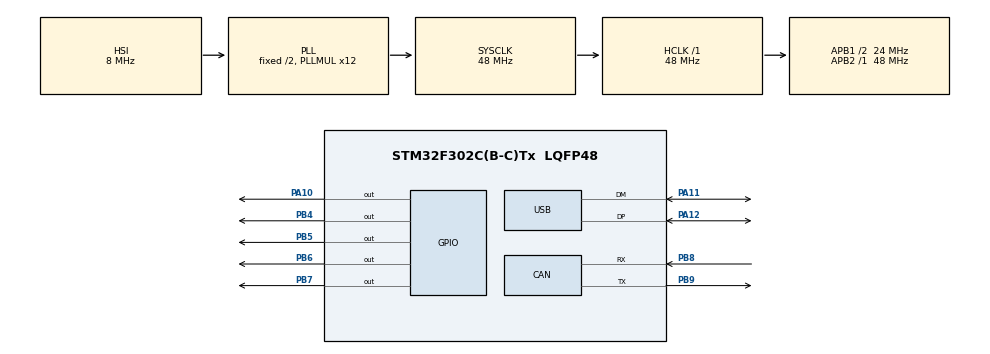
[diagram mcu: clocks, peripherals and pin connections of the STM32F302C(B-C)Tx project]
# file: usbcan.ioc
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CAN.CalculateTimeQuantum=666.6666666666666
Mcu.Family=STM32F3
Mcu.Name=STM32F302C(B-C)Tx
Mcu.Package=LQFP48
NVIC.PriorityGroup=NVIC_PRIORITYGROUP_4
NVIC.USB_LP_IRQn=true\:0\:0\:false\:false\:true\:false\:true
PA10.Signal=GPIO_Output
PA11.Mode=Device
PA11.Signal=USB_DM
PA12.Mode=Device
PA12.Signal=USB_DP
PA13.Mode=Serial_Wire
PA13.Signal=SYS_JTMS-SWDIO
PA14.Mode=Serial_Wire
PA14.Signal=SYS_JTCK-SWCLK
PB4.Signal=GPIO_Output
PB5.Signal=GPIO_Output
PB6.Signal=GPIO_Output
PB7.Signal=GPIO_Output
PB8.Mode=Master
PB8.Signal=CAN_RX
PB9.Mode=Master
PB9.Signal=CAN_TX
ProjectManager.HeapSize=0x200
ProjectManager.StackSize=0x400
ProjectManager.TargetToolchain=STM32CubeIDE
RCC.AHBFreq_Value=48000000
RCC.APB1CLKDivider=RCC_HCLK_DIV2
RCC.APB1Freq_Value=24000000
RCC.APB1TimFreq_Value=48000000
RCC.APB2Freq_Value=48000000
RCC.APB2TimFreq_Value=48000000
RCC.CortexFreq_Value=48000000
RCC.HCLKFreq_Value=48000000
RCC.HSE_VALUE=8000000
RCC.HSI_VALUE=8000000
RCC.LSE_VALUE=32768
RCC.PLLMUL=RCC_PLL_MUL12
RCC.PLLSource=RCC_PLLSOURCE_HSI
RCC.PLLSourceVirtualString=RCC_PLLSOURCE_HSI
RCC.SYSCLKFreq_VALUE=48000000
RCC.SYSCLKSourceVirtual=RCC_SYSCLKSOURCE_PLLCLK
RCC.USBFreq_Value=48000000
USB_DEVICE.CLASS_NAME_FS=CDC
USB_DEVICE.VirtualMode=Cdc
USB_DEVICE.VirtualModeFS=Cdc_FS
VP_USB_DEVICE_VS_USB_DEVICE_CDC_FS.Mode=CDC_FS
board=custom

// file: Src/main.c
/* USER CODE BEGIN Header */
/**
  ******************************************************************************
  * @file           : main.c
  * @brief          : Main program body
  ******************************************************************************
  * @attention
  *
  * <h2><center>&copy; Copyright (c) 2019 STMicroelectronics.
  * All rights reserved.</center></h2>
  *
  * This software component is licensed by ST under Ultimate Liberty license
  * SLA0044, the "License"; You may not use this file except in compliance with
  * the License. You may obtain a copy of the License at:
  *                             www.st.com/SLA0044
  *
  ******************************************************************************
  */
/* USER CODE END Header */

#include "main.h"
#include "usb_device.h"

CAN_HandleTypeDef hcan;

void SystemClock_Config(void);
static void MX_GPIO_Init(void);
static void MX_CAN_Init(void);

/* USER CODE BEGIN 0 */

extern USBD_HandleTypeDef hUsbDeviceFS;
/* USER CODE END 0 */

int main(void)
{

  /* MCU Configuration--------------------------------------------------------*/

  /* Reset of all peripherals, Initializes the Flash interface and the Systick. */
  HAL_Init();

  /* Configure the system clock */
  SystemClock_Config();

  /* Initialize all configured peripherals */
  MX_GPIO_Init();
  MX_CAN_Init();
  MX_USB_DEVICE_Init();
  /* USER CODE BEGIN 2 */

  uint8_t buf[64];
  int i = 0;
  for(i =0;i<64;i++)
  {
	  buf[i] = 'A'+i;
  }

  //GPIOB->BSRR = GPIO_BSRR_BS_5;
  //GPIOB->BSRR = GPIO_BSRR_BS_6;
  //GPIOB->BSRR = GPIO_BSRR_BS_7;
  HAL_Delay(100);
  GPIOA->BSRR = GPIO_BSRR_BS_10;
  HAL_Delay(500);

  /* USER CODE END 2 */

  /* Infinite loop */
  while (1)
  {

    /* USER CODE BEGIN 3 */

	  CDC_Transmit_FS(buf, 64);

	  //PCD_HandleTypeDef *hpcd = hUsbDeviceFS.pData;
	  //USBD_LL_FlushEP(hpcd->Instance, 0x81);

	  GPIOB->BSRR = GPIO_BSRR_BR_6;
	  HAL_Delay(25);
	  GPIOB->BSRR = GPIO_BSRR_BS_6;
	  HAL_Delay(25);
  }
  /* USER CODE END 3 */
}

void SystemClock_Config(void)
{
  RCC_OscInitTypeDef RCC_OscInitStruct = {0};
  RCC_ClkInitTypeDef RCC_ClkInitStruct = {0};
  RCC_PeriphCLKInitTypeDef PeriphClkInit = {0};

  /** Initializes the CPU, AHB and APB busses clocks
  */
  RCC_OscInitStruct.OscillatorType = RCC_OSCILLATORTYPE_HSI;
  RCC_OscInitStruct.HSIState = RCC_HSI_ON;
  RCC_OscInitStruct.HSICalibrationValue = RCC_HSICALIBRATION_DEFAULT;
  RCC_OscInitStruct.PLL.PLLState = RCC_PLL_ON;
  RCC_OscInitStruct.PLL.PLLSource = RCC_PLLSOURCE_HSI;
  RCC_OscInitStruct.PLL.PLLMUL = RCC_PLL_MUL12;
  if (HAL_RCC_OscConfig(&RCC_OscInitStruct) != HAL_OK)
  {
    Error_Handler();
  }
  /** Initializes the CPU, AHB and APB busses clocks
  */
  RCC_ClkInitStruct.ClockType = RCC_CLOCKTYPE_HCLK|RCC_CLOCKTYPE_SYSCLK
                              |RCC_CLOCKTYPE_PCLK1|RCC_CLOCKTYPE_PCLK2;
  RCC_ClkInitStruct.SYSCLKSource = RCC_SYSCLKSOURCE_PLLCLK;
  RCC_ClkInitStruct.AHBCLKDivider = RCC_SYSCLK_DIV1;
  RCC_ClkInitStruct.APB1CLKDivider = RCC_HCLK_DIV2;
  RCC_ClkInitStruct.APB2CLKDivider = RCC_HCLK_DIV1;

  if (HAL_RCC_ClockConfig(&RCC_ClkInitStruct, FLASH_LATENCY_1) != HAL_OK)
  {
    Error_Handler();
  }
  PeriphClkInit.PeriphClockSelection = RCC_PERIPHCLK_USB;
  PeriphClkInit.USBClockSelection = RCC_USBCLKSOURCE_PLL;
  if (HAL_RCCEx_PeriphCLKConfig(&PeriphClkInit) != HAL_OK)
  {
    Error_Handler();
  }
}

static void MX_CAN_Init(void)
{

  hcan.Instance = CAN;
  hcan.Init.Prescaler = 16;
  hcan.Init.Mode = CAN_MODE_NORMAL;
  hcan.Init.SyncJumpWidth = CAN_SJW_1TQ;
  hcan.Init.TimeSeg1 = CAN_BS1_1TQ;
  hcan.Init.TimeSeg2 = CAN_BS2_1TQ;
  hcan.Init.TimeTriggeredMode = DISABLE;
  hcan.Init.AutoBusOff = DISABLE;
  hcan.Init.AutoWakeUp = DISABLE;
  hcan.Init.AutoRetransmission = DISABLE;
  hcan.Init.ReceiveFifoLocked = DISABLE;
  hcan.Init.TransmitFifoPriority = DISABLE;
  if (HAL_CAN_Init(&hcan) != HAL_OK)
  {
    Error_Handler();
  }

}

static void MX_GPIO_Init(void)
{
  GPIO_InitTypeDef GPIO_InitStruct = {0};

  /* GPIO Ports Clock Enable */
  __HAL_RCC_GPIOA_CLK_ENABLE();
  __HAL_RCC_GPIOB_CLK_ENABLE();

  /*Configure GPIO pin Output Level */
  HAL_GPIO_WritePin(GPIOA, GPIO_PIN_10, GPIO_PIN_RESET);

  /*Configure GPIO pin Output Level */
  HAL_GPIO_WritePin(GPIOB, GPIO_PIN_4|GPIO_PIN_5|GPIO_PIN_6|GPIO_PIN_7, GPIO_PIN_RESET);

  /*Configure GPIO pin : PA10 */
  GPIO_InitStruct.Pin = GPIO_PIN_10;
  GPIO_InitStruct.Mode = GPIO_MODE_OUTPUT_PP;
  GPIO_InitStruct.Pull = GPIO_NOPULL;
  GPIO_InitStruct.Speed = GPIO_SPEED_FREQ_LOW;
  HAL_GPIO_Init(GPIOA, &GPIO_InitStruct);

  /*Configure GPIO pins : PB4 PB5 PB6 PB7 */
  GPIO_InitStruct.Pin = GPIO_PIN_4|GPIO_PIN_5|GPIO_PIN_6|GPIO_PIN_7;
  GPIO_InitStruct.Mode = GPIO_MODE_OUTPUT_PP;
  GPIO_InitStruct.Pull = GPIO_NOPULL;
  GPIO_InitStruct.Speed = GPIO_SPEED_FREQ_LOW;
  HAL_GPIO_Init(GPIOB, &GPIO_InitStruct);

}

void Error_Handler(void)
{
}

/************************ (C) COPYRIGHT STMicroelectronics *****END OF FILE****/
